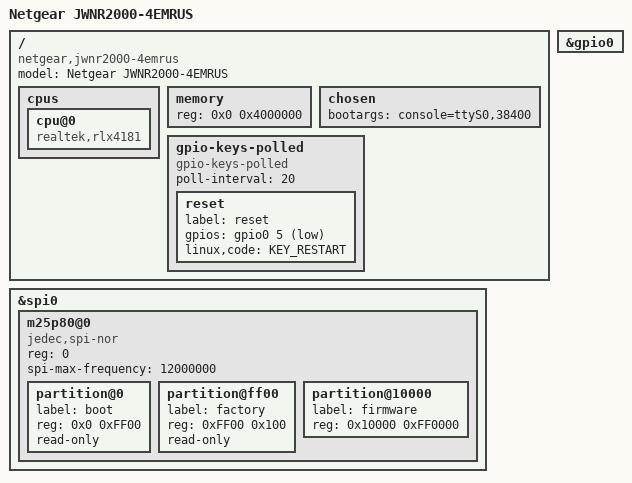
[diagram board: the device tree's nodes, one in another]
// SPDX-License-Identifier: GPL-2.0
/dts-v1/;

#include "RTL819X.dtsi"

#include <dt-bindings/gpio/gpio.h>
#include <dt-bindings/input/input.h>

/ {
	compatible = "netgear,jwnr2000-4emrus", "realtek,rtl819x-soc";
	model = "Netgear JWNR2000-4EMRUS";

	cpus {
		cpu@0 {
			compatible = "realtek,rlx4181";
		};
	};

	memory {
		device_type = "memory";
		reg = <0x0 0x4000000>;
	};

	chosen {
		bootargs = "console=ttyS0,38400";
	};

	gpio-keys-polled {
		compatible = "gpio-keys-polled";
		#address-cells = <1>;
		#size-cells = <0>;
		poll-interval = <20>;

		reset {
			label = "reset";
			gpios = <&gpio0 5 GPIO_ACTIVE_LOW>;
			linux,code = <KEY_RESTART>;
		};
	};
};

&gpio0 {
	status = "okay";
};

&spi0 {
	status = "okay";

	m25p80@0 {
		#address-cells = <1>;
		#size-cells = <1>;
		compatible = "jedec,spi-nor";
		reg = <0>;
		spi-max-frequency = <12000000>;

		partition@0 {
			label = "boot";
			reg = <0x0 0xFF00>;
			read-only;
		};

		partition@ff00 {
			label = "factory";
			reg = <0xFF00 0x100>;
			read-only;
		};

		partition@10000 {
			label = "firmware";
			reg = <0x10000 0xFF0000>;
		};
	};
};
